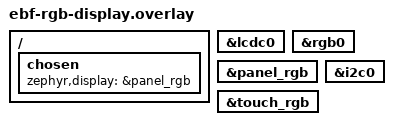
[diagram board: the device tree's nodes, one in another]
/ {
	chosen {
		zephyr,display = &panel_rgb;
	};
};

&lcdc0 { status = "okay"; };
&rgb0 { status = "okay"; };
&panel_rgb { status = "okay"; };
&i2c0 { status = "okay"; };
&touch_rgb { status = "okay"; };
